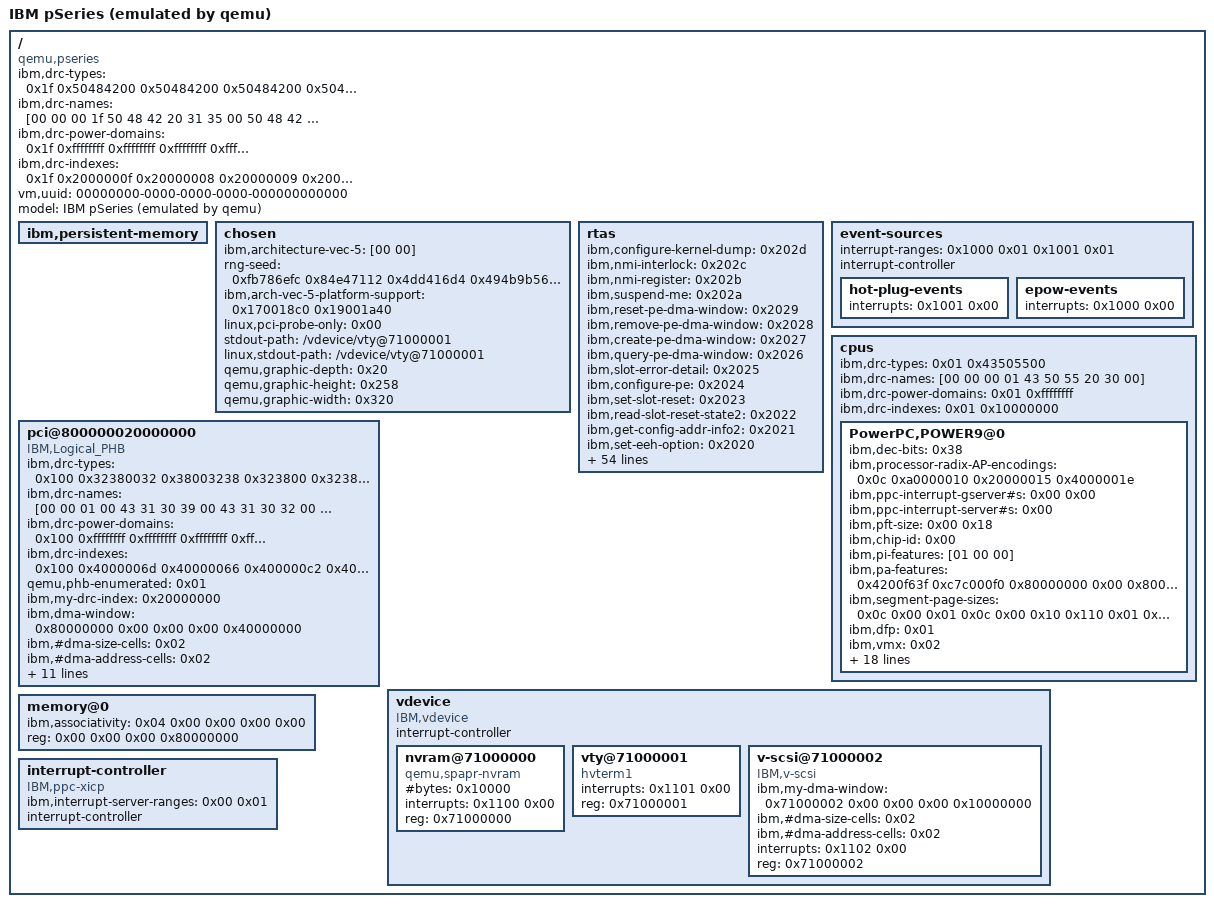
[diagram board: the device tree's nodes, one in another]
/dts-v1/;

/ {
	ibm,drc-types = <0x1f 0x50484200 0x50484200 0x50484200 0x50484200 0x50484200 0x50484200 0x50484200 0x50484200 0x50484200 0x50484200 0x50484200 0x50484200 0x50484200 0x50484200 0x50484200 0x50484200 0x50484200 0x50484200 0x50484200 0x50484200 0x50484200 0x50484200 0x50484200 0x50484200 0x50484200 0x50484200 0x50484200 0x50484200 0x50484200 0x50484200 0x50484200>;
	ibm,drc-names = [00 00 00 1f 50 48 42 20 31 35 00 50 48 42 20 38 00 50 48 42 20 39 00 50 48 42 20 31 36 00 50 48 42 20 31 37 00 50 48 42 20 31 38 00 50 48 42 20 31 39 00 50 48 42 20 32 36 00 50 48 42 20 32 30 00 50 48 42 20 32 37 00 50 48 42 20 32 31 00 50 48 42 20 32 38 00 50 48 42 20 32 39 00 50 48 42 20 32 32 00 50 48 42 20 33 30 00 50 48 42 20 32 33 00 50 48 42 20 32 34 00 50 48 42 20 32 35 00 50 48 42 20 30 00 50 48 42 20 31 00 50 48 42 20 32 00 50 48 42 20 31 30 00 50 48 42 20 33 00 50 48 42 20 31 31 00 50 48 42 20 34 00 50 48 42 20 31 32 00 50 48 42 20 35 00 50 48 42 20 31 33 00 50 48 42 20 36 00 50 48 42 20 31 34 00 50 48 42 20 37 00];
	ibm,drc-power-domains = <0x1f 0xffffffff 0xffffffff 0xffffffff 0xffffffff 0xffffffff 0xffffffff 0xffffffff 0xffffffff 0xffffffff 0xffffffff 0xffffffff 0xffffffff 0xffffffff 0xffffffff 0xffffffff 0xffffffff 0xffffffff 0xffffffff 0xffffffff 0xffffffff 0xffffffff 0xffffffff 0xffffffff 0xffffffff 0xffffffff 0xffffffff 0xffffffff 0xffffffff 0xffffffff 0xffffffff 0xffffffff>;
	ibm,drc-indexes = <0x1f 0x2000000f 0x20000008 0x20000009 0x20000010 0x20000011 0x20000012 0x20000013 0x2000001a 0x20000014 0x2000001b 0x20000015 0x2000001c 0x2000001d 0x20000016 0x2000001e 0x20000017 0x20000018 0x20000019 0x20000000 0x20000001 0x20000002 0x2000000a 0x20000003 0x2000000b 0x20000004 0x2000000c 0x20000005 0x2000000d 0x20000006 0x2000000e 0x20000007>;
	#size-cells = <0x02>;
	#address-cells = <0x02>;
	vm,uuid = "00000000-0000-0000-0000-000000000000";
	compatible = "qemu,pseries";
	model = "IBM pSeries (emulated by qemu)";
	device_type = "chrp";

	ibm,persistent-memory {
		device_type = "ibm,persistent-memory";
		#size-cells = <0x00>;
		#address-cells = <0x01>;
	};

	chosen {
		ibm,architecture-vec-5 = [00 00];
		rng-seed = <0xfb786efc 0x84e47112 0x4dd416d4 0x494b9b56 0x7fbd4a18 0x85047fd8 0xc287ff82 0xabd18130>;
		ibm,arch-vec-5-platform-support = <0x170018c0 0x19001a40>;
		linux,pci-probe-only = <0x00>;
		stdout-path = "/vdevice/vty@71000001";
		linux,stdout-path = "/vdevice/vty@71000001";
		qemu,graphic-depth = <0x20>;
		qemu,graphic-height = <0x258>;
		qemu,graphic-width = <0x320>;
	};

	rtas {
		ibm,configure-kernel-dump = <0x202d>;
		ibm,nmi-interlock = <0x202c>;
		ibm,nmi-register = <0x202b>;
		ibm,suspend-me = <0x202a>;
		ibm,reset-pe-dma-window = <0x2029>;
		ibm,remove-pe-dma-window = <0x2028>;
		ibm,create-pe-dma-window = <0x2027>;
		ibm,query-pe-dma-window = <0x2026>;
		ibm,slot-error-detail = <0x2025>;
		ibm,configure-pe = <0x2024>;
		ibm,set-slot-reset = <0x2023>;
		ibm,read-slot-reset-state2 = <0x2022>;
		ibm,get-config-addr-info2 = <0x2021>;
		ibm,set-eeh-option = <0x2020>;
		ibm,os-term = <0x201f>;
		ibm,configure-connector = <0x201e>;
		get-sensor-state = <0x201d>;
		get-power-level = <0x201c>;
		set-power-level = <0x201b>;
		set-indicator = <0x201a>;
		ibm,change-msi = <0x2019>;
		ibm,query-interrupt-source-number = <0x2018>;
		ibm,write-pci-config = <0x2017>;
		ibm,read-pci-config = <0x2016>;
		write-pci-config = <0x2015>;
		read-pci-config = <0x2014>;
		nvram-store = <0x2013>;
		nvram-fetch = <0x2012>;
		quiesce = <0x2011>;
		ibm,set-tce-bypass = <0x2010>;
		event-scan = <0x200f>;
		check-exception = <0x200e>;
		ibm,int-on = <0x200d>;
		ibm,int-off = <0x200c>;
		ibm,get-xive = <0x200b>;
		ibm,set-xive = <0x200a>;
		ibm,set-system-parameter = <0x2009>;
		ibm,get-system-parameter = <0x2008>;
		stop-self = <0x2007>;
		start-cpu = <0x2006>;
		query-cpu-stopped-state = <0x2005>;
		system-reboot = <0x2004>;
		power-off = <0x2003>;
		set-time-of-day = <0x2002>;
		get-time-of-day = <0x2001>;
		display-character = <0x2000>;
		ibm,configure-kernel-dump-sizes = <0x01 0x00 0x510 0x02 0x00 0x00>;
		ibm,configure-kernel-dump-version = <0x1000100>;
		ibm,lrdr-capacity = <0x00 0x80000000 0x00 0x10000000 0x01>;
		ibm,extended-os-term;
		ibm,change-msix-capable;
		rtas-event-scan-rate = <0x01>;
		rtas-error-log-max = <0x800>;
		rtas-size = <0x82c>;
		ibm,max-associativity-domains = <0x04 0x00 0x00 0x00 0x01>;
		ibm,associativity-reference-points = <0x04 0x04 0x02>;
		qemu,hypertas-functions = "hcall-memop1";
		ibm,hypertas-functions = "hcall-pft", "hcall-term", "hcall-dabr", "hcall-interrupt", "hcall-tce", "hcall-vio", "hcall-splpar", "hcall-join", "hcall-bulk", "hcall-set-mode", "hcall-sprg0", "hcall-copy", "hcall-debug", "hcall-vphn", "hcall-multi-tce", "hcall-hpt-resize", "hcall-watchdog";
	};

	event-sources {
		interrupt-ranges = <0x1000 0x01 0x1001 0x01>;
		#interrupt-cells = <0x02>;
		interrupt-controller;

		hot-plug-events {
			interrupts = <0x1001 0x00>;
		};

		epow-events {
			interrupts = <0x1000 0x00>;
		};
	};

	cpus {
		ibm,drc-types = <0x01 0x43505500>;
		ibm,drc-names = [00 00 00 01 43 50 55 20 30 00];
		ibm,drc-power-domains = <0x01 0xffffffff>;
		ibm,drc-indexes = <0x01 0x10000000>;
		#size-cells = <0x00>;
		#address-cells = <0x01>;

		PowerPC,POWER9@0 {
			ibm,dec-bits = <0x38>;
			ibm,processor-radix-AP-encodings = <0x0c 0xa0000010 0x20000015 0x4000001e>;
			ibm,ppc-interrupt-gserver#s = <0x00 0x00>;
			ibm,ppc-interrupt-server#s = <0x00>;
			ibm,pft-size = <0x00 0x18>;
			ibm,chip-id = <0x00>;
			ibm,pi-features = [01 00 00];
			ibm,pa-features = <0x4200f63f 0xc7c000f0 0x80000000 0x00 0x8000 0x80008000 0x8000 0x80008000 0x8000 0xc0000000 0x8000 0x80008000 0x80008000 0x80008000 0x80008000 0x80008000 0x80000000>;
			ibm,segment-page-sizes = <0x0c 0x00 0x01 0x0c 0x00 0x10 0x110 0x01 0x10 0x01>;
			ibm,dfp = <0x01>;
			ibm,vmx = <0x02>;
			ibm,processor-segment-sizes = <0x1c 0x28 0xffffffff 0xffffffff>;
			ibm,spurr = <0x01>;
			ibm,purr = <0x01>;
			64-bit;
			status = "okay";
			ibm,slb-size = <0x20>;
			slb-size = <0x20>;
			clock-frequency = <0x3b9aca00>;
			timebase-frequency = <0x1e848000>;
			i-cache-size = <0x8000>;
			d-cache-size = <0x8000>;
			i-cache-line-size = <0x80>;
			i-cache-block-size = <0x80>;
			d-cache-line-size = <0x80>;
			d-cache-block-size = <0x80>;
			cpu-version = <0x4e1202>;
			device_type = "cpu";
			reg = <0x00>;
			ibm,my-drc-index = <0x10000000>;
		};
	};

	pci@800000020000000 {
		ibm,drc-types = <0x100 0x32380032 0x38003238 0x323800 0x32380032 0x38003238 0x323800 0x32380032 0x38003238 0x323800 0x32380032 0x38003238 0x323800 0x32380032 0x38003238 0x323800 0x32380032 0x38003238 0x323800 0x32380032 0x38003238 0x323800 0x32380032 0x38003238 0x323800 0x32380032 0x38003238 0x323800 0x32380032 0x38003238 0x323800 0x32380032 0x38003238 0x323800 0x32380032 0x38003238 0x323800 0x32380032 0x38003238 0x323800 0x32380032 0x38003238 0x323800 0x32380032 0x38003238 0x323800 0x32380032 0x38003238 0x323800 0x32380032 0x38003238 0x323800 0x32380032 0x38003238 0x323800 0x32380032 0x38003238 0x323800 0x32380032 0x38003238 0x323800 0x32380032 0x38003238 0x323800 0x32380032 0x38003238 0x323800 0x32380032 0x38003238 0x323800 0x32380032 0x38003238 0x323800 0x32380032 0x38003238 0x323800 0x32380032 0x38003238 0x323800 0x32380032 0x38003238 0x323800 0x32380032 0x38003238 0x323800 0x32380032 0x38003238 0x323800 0x32380032 0x38003238 0x323800 0x32380032 0x38003238 0x323800 0x32380032 0x38003238 0x323800 0x32380032 0x38003238 0x323800 0x32380032 0x38003238 0x323800 0x32380032 0x38003238 0x323800 0x32380032 0x38003238 0x323800 0x32380032 0x38003238 0x323800 0x32380032 0x38003238 0x323800 0x32380032 0x38003238 0x323800 0x32380032 0x38003238 0x323800 0x32380032 0x38003238 0x323800 0x32380032 0x38003238 0x323800 0x32380032 0x38003238 0x323800 0x32380032 0x38003238 0x323800 0x32380032 0x38003238 0x323800 0x32380032 0x38003238 0x323800 0x32380032 0x38003238 0x323800 0x32380032 0x38003238 0x323800 0x32380032 0x38003238 0x323800 0x32380032 0x38003238 0x323800 0x32380032 0x38003238 0x323800 0x32380032 0x38003238 0x323800 0x32380032 0x38003238 0x323800 0x32380032 0x38003238 0x323800 0x32380032 0x38003238 0x323800 0x32380032 0x38003238 0x323800 0x32380032 0x38003238 0x323800 0x32380032 0x38003238 0x323800 0x32380032 0x38003238 0x323800 0x32380032 0x38003238 0x323800 0x32380032 0x38003238 0x323800 0x32380032 0x38003238 0x323800 0x32380032 0x38003238 0x323800 0x32380032 0x38003238 0x323800>;
		ibm,drc-names = [00 00 01 00 43 31 30 39 00 43 31 30 32 00 43 31 39 34 00 43 31 34 34 00 43 31 31 30 00 43 33 32 00 43 32 30 32 00 43 31 30 33 00 43 31 39 35 00 43 31 34 35 00 43 31 31 31 00 43 33 33 00 43 32 30 33 00 43 31 30 34 00 43 31 39 36 00 43 31 34 36 00 43 33 34 00 43 32 30 34 00 43 31 30 35 00 43 31 35 34 00 43 31 39 37 00 43 31 34 37 00 43 34 32 00 43 33 35 00 43 32 30 35 00 43 31 35 35 00 43 31 39 38 00 43 31 34 38 00 43 34 33 00 43 32 34 30 00 43 33 36 00 43 32 30 36 00 43 31 35 36 00 43 31 39 39 00 43 31 34 39 00 43 34 34 00 43 32 34 31 00 43 33 37 00 43 32 30 37 00 43 31 35 37 00 43 32 30 30 00 43 31 35 30 00 43 34 35 00 43 32 34 32 00 43 33 38 00 43 31 35 38 00 43 38 30 00 43 32 30 31 00 43 31 35 31 00 43 34 36 00 43 32 34 33 00 43 33 39 00 43 32 35 30 00 43 31 35 39 00 43 38 31 00 43 31 35 32 00 43 34 37 00 43 32 34 34 00 43 34 30 00 43 32 35 31 00 43 38 32 00 43 31 35 33 00 43 32 35 32 00 43 32 34 35 00 43 34 31 00 43 39 30 00 43 38 33 00 43 32 35 33 00 43 32 34 36 00 43 39 31 00 43 38 34 00 43 32 35 34 00 43 31 37 36 00 43 32 34 37 00 43 39 32 00 43 38 35 00 43 32 35 35 00 43 31 37 37 00 43 32 34 38 00 43 39 33 00 43 38 36 00 43 31 37 38 00 43 31 32 38 00 43 32 34 39 00 43 39 34 00 43 31 36 00 43 31 38 36 00 43 38 37 00 43 31 37 39 00 43 31 32 39 00 43 39 35 00 43 31 37 00 43 31 38 37 00 43 38 38 00 43 31 38 30 00 43 31 33 30 00 43 31 38 00 43 31 38 38 00 43 38 39 00 43 31 33 38 00 43 31 38 31 00 43 31 33 31 00 43 32 36 00 43 31 39 00 43 31 38 39 00 43 31 33 39 00 43 31 38 32 00 43 31 33 32 00 43 32 37 00 43 32 32 34 00 43 32 30 00 43 31 39 30 00 43 31 34 30 00 43 31 38 33 00 43 31 33 33 00 43 32 38 00 43 32 32 35 00 43 32 31 00 43 31 39 31 00 43 31 34 31 00 43 31 38 34 00 43 31 33 34 00 43 32 39 00 43 32 32 36 00 43 32 32 00 43 31 34 32 00 43 31 38 35 00 43 36 34 00 43 31 33 35 00 43 33 30 00 43 32 32 37 00 43 32 33 00 43 32 33 34 00 43 31 34 33 00 43 36 35 00 43 31 33 36 00 43 33 31 00 43 32 32 38 00 43 32 34 00 43 32 33 35 00 43 36 36 00 43 31 33 37 00 43 32 33 36 00 43 32 32 39 00 43 32 35 00 43 37 34 00 43 36 37 00 43 32 33 37 00 43 32 33 30 00 43 37 35 00 43 36 38 00 43 32 33 38 00 43 31 36 30 00 43 32 33 31 00 43 37 36 00 43 36 39 00 43 32 33 39 00 43 31 36 31 00 43 32 33 32 00 43 37 37 00 43 37 30 00 43 31 36 32 00 43 31 31 32 00 43 32 33 33 00 43 37 38 00 43 30 00 43 31 37 30 00 43 37 31 00 43 31 36 33 00 43 31 31 33 00 43 37 39 00 43 31 00 43 31 37 31 00 43 37 32 00 43 31 36 34 00 43 31 31 34 00 43 32 00 43 31 37 32 00 43 37 33 00 43 31 32 32 00 43 31 36 35 00 43 31 31 35 00 43 31 30 00 43 33 00 43 31 37 33 00 43 31 32 33 00 43 31 36 36 00 43 31 31 36 00 43 31 31 00 43 32 30 38 00 43 34 00 43 31 37 34 00 43 31 32 34 00 43 31 36 37 00 43 31 31 37 00 43 31 32 00 43 32 30 39 00 43 35 00 43 31 37 35 00 43 31 32 35 00 43 31 36 38 00 43 31 31 38 00 43 31 33 00 43 32 31 30 00 43 36 00 43 31 32 36 00 43 34 38 00 43 31 31 39 00 43 31 34 00 43 32 31 31 00 43 37 00 43 32 31 38 00 43 31 36 39 00 43 34 39 00 43 31 32 30 00 43 31 35 00 43 31 32 37 00 43 38 00 43 32 31 32 00 43 35 30 00 43 32 31 39 00 43 31 32 31 00 43 32 32 30 00 43 32 31 33 00 43 39 00 43 35 38 00 43 35 31 00 43 32 32 31 00 43 32 31 34 00 43 35 39 00 43 35 32 00 43 32 32 32 00 43 32 31 35 00 43 36 30 00 43 35 33 00 43 32 32 33 00 43 32 31 36 00 43 36 31 00 43 35 34 00 43 39 36 00 43 32 31 37 00 43 36 32 00 43 35 35 00 43 39 37 00 43 36 33 00 43 35 36 00 43 39 38 00 43 35 37 00 43 31 30 36 00 43 39 39 00 43 31 30 37 00 43 31 30 30 00 43 31 39 32 00 43 31 30 38 00 43 31 30 31 00 43 31 39 33 00];
		ibm,drc-power-domains = <0x100 0xffffffff 0xffffffff 0xffffffff 0xffffffff 0xffffffff 0xffffffff 0xffffffff 0xffffffff 0xffffffff 0xffffffff 0xffffffff 0xffffffff 0xffffffff 0xffffffff 0xffffffff 0xffffffff 0xffffffff 0xffffffff 0xffffffff 0xffffffff 0xffffffff 0xffffffff 0xffffffff 0xffffffff 0xffffffff 0xffffffff 0xffffffff 0xffffffff 0xffffffff 0xffffffff 0xffffffff 0xffffffff 0xffffffff 0xffffffff 0xffffffff 0xffffffff 0xffffffff 0xffffffff 0xffffffff 0xffffffff 0xffffffff 0xffffffff 0xffffffff 0xffffffff 0xffffffff 0xffffffff 0xffffffff 0xffffffff 0xffffffff 0xffffffff 0xffffffff 0xffffffff 0xffffffff 0xffffffff 0xffffffff 0xffffffff 0xffffffff 0xffffffff 0xffffffff 0xffffffff 0xffffffff 0xffffffff 0xffffffff 0xffffffff 0xffffffff 0xffffffff 0xffffffff 0xffffffff 0xffffffff 0xffffffff 0xffffffff 0xffffffff 0xffffffff 0xffffffff 0xffffffff 0xffffffff 0xffffffff 0xffffffff 0xffffffff 0xffffffff 0xffffffff 0xffffffff 0xffffffff 0xffffffff 0xffffffff 0xffffffff 0xffffffff 0xffffffff 0xffffffff 0xffffffff 0xffffffff 0xffffffff 0xffffffff 0xffffffff 0xffffffff 0xffffffff 0xffffffff 0xffffffff 0xffffffff 0xffffffff 0xffffffff 0xffffffff 0xffffffff 0xffffffff 0xffffffff 0xffffffff 0xffffffff 0xffffffff 0xffffffff 0xffffffff 0xffffffff 0xffffffff 0xffffffff 0xffffffff 0xffffffff 0xffffffff 0xffffffff 0xffffffff 0xffffffff 0xffffffff 0xffffffff 0xffffffff 0xffffffff 0xffffffff 0xffffffff 0xffffffff 0xffffffff 0xffffffff 0xffffffff 0xffffffff 0xffffffff 0xffffffff 0xffffffff 0xffffffff 0xffffffff 0xffffffff 0xffffffff 0xffffffff 0xffffffff 0xffffffff 0xffffffff 0xffffffff 0xffffffff 0xffffffff 0xffffffff 0xffffffff 0xffffffff 0xffffffff 0xffffffff 0xffffffff 0xffffffff 0xffffffff 0xffffffff 0xffffffff 0xffffffff 0xffffffff 0xffffffff 0xffffffff 0xffffffff 0xffffffff 0xffffffff 0xffffffff 0xffffffff 0xffffffff 0xffffffff 0xffffffff 0xffffffff 0xffffffff 0xffffffff 0xffffffff 0xffffffff 0xffffffff 0xffffffff 0xffffffff 0xffffffff 0xffffffff 0xffffffff 0xffffffff 0xffffffff 0xffffffff 0xffffffff 0xffffffff 0xffffffff 0xffffffff 0xffffffff 0xffffffff 0xffffffff 0xffffffff 0xffffffff 0xffffffff 0xffffffff 0xffffffff 0xffffffff 0xffffffff 0xffffffff 0xffffffff 0xffffffff 0xffffffff 0xffffffff 0xffffffff 0xffffffff 0xffffffff 0xffffffff 0xffffffff 0xffffffff 0xffffffff 0xffffffff 0xffffffff 0xffffffff 0xffffffff 0xffffffff 0xffffffff 0xffffffff 0xffffffff 0xffffffff 0xffffffff 0xffffffff 0xffffffff 0xffffffff 0xffffffff 0xffffffff 0xffffffff 0xffffffff 0xffffffff 0xffffffff 0xffffffff 0xffffffff 0xffffffff 0xffffffff 0xffffffff 0xffffffff 0xffffffff 0xffffffff 0xffffffff 0xffffffff 0xffffffff 0xffffffff 0xffffffff 0xffffffff 0xffffffff 0xffffffff 0xffffffff 0xffffffff 0xffffffff 0xffffffff 0xffffffff 0xffffffff 0xffffffff 0xffffffff 0xffffffff 0xffffffff 0xffffffff 0xffffffff 0xffffffff 0xffffffff 0xffffffff>;
		ibm,drc-indexes = <0x100 0x4000006d 0x40000066 0x400000c2 0x40000090 0x4000006e 0x40000020 0x400000ca 0x40000067 0x400000c3 0x40000091 0x4000006f 0x40000021 0x400000cb 0x40000068 0x400000c4 0x40000092 0x40000022 0x400000cc 0x40000069 0x4000009a 0x400000c5 0x40000093 0x4000002a 0x40000023 0x400000cd 0x4000009b 0x400000c6 0x40000094 0x4000002b 0x400000f0 0x40000024 0x400000ce 0x4000009c 0x400000c7 0x40000095 0x4000002c 0x400000f1 0x40000025 0x400000cf 0x4000009d 0x400000c8 0x40000096 0x4000002d 0x400000f2 0x40000026 0x4000009e 0x40000050 0x400000c9 0x40000097 0x4000002e 0x400000f3 0x40000027 0x400000fa 0x4000009f 0x40000051 0x40000098 0x4000002f 0x400000f4 0x40000028 0x400000fb 0x40000052 0x40000099 0x400000fc 0x400000f5 0x40000029 0x4000005a 0x40000053 0x400000fd 0x400000f6 0x4000005b 0x40000054 0x400000fe 0x400000b0 0x400000f7 0x4000005c 0x40000055 0x400000ff 0x400000b1 0x400000f8 0x4000005d 0x40000056 0x400000b2 0x40000080 0x400000f9 0x4000005e 0x40000010 0x400000ba 0x40000057 0x400000b3 0x40000081 0x4000005f 0x40000011 0x400000bb 0x40000058 0x400000b4 0x40000082 0x40000012 0x400000bc 0x40000059 0x4000008a 0x400000b5 0x40000083 0x4000001a 0x40000013 0x400000bd 0x4000008b 0x400000b6 0x40000084 0x4000001b 0x400000e0 0x40000014 0x400000be 0x4000008c 0x400000b7 0x40000085 0x4000001c 0x400000e1 0x40000015 0x400000bf 0x4000008d 0x400000b8 0x40000086 0x4000001d 0x400000e2 0x40000016 0x4000008e 0x400000b9 0x40000040 0x40000087 0x4000001e 0x400000e3 0x40000017 0x400000ea 0x4000008f 0x40000041 0x40000088 0x4000001f 0x400000e4 0x40000018 0x400000eb 0x40000042 0x40000089 0x400000ec 0x400000e5 0x40000019 0x4000004a 0x40000043 0x400000ed 0x400000e6 0x4000004b 0x40000044 0x400000ee 0x400000a0 0x400000e7 0x4000004c 0x40000045 0x400000ef 0x400000a1 0x400000e8 0x4000004d 0x40000046 0x400000a2 0x40000070 0x400000e9 0x4000004e 0x40000000 0x400000aa 0x40000047 0x400000a3 0x40000071 0x4000004f 0x40000001 0x400000ab 0x40000048 0x400000a4 0x40000072 0x40000002 0x400000ac 0x40000049 0x4000007a 0x400000a5 0x40000073 0x4000000a 0x40000003 0x400000ad 0x4000007b 0x400000a6 0x40000074 0x4000000b 0x400000d0 0x40000004 0x400000ae 0x4000007c 0x400000a7 0x40000075 0x4000000c 0x400000d1 0x40000005 0x400000af 0x4000007d 0x400000a8 0x40000076 0x4000000d 0x400000d2 0x40000006 0x4000007e 0x40000030 0x40000077 0x4000000e 0x400000d3 0x40000007 0x400000da 0x400000a9 0x40000031 0x40000078 0x4000000f 0x4000007f 0x40000008 0x400000d4 0x40000032 0x400000db 0x40000079 0x400000dc 0x400000d5 0x40000009 0x4000003a 0x40000033 0x400000dd 0x400000d6 0x4000003b 0x40000034 0x400000de 0x400000d7 0x4000003c 0x40000035 0x400000df 0x400000d8 0x4000003d 0x40000036 0x40000060 0x400000d9 0x4000003e 0x40000037 0x40000061 0x4000003f 0x40000038 0x40000062 0x40000039 0x4000006a 0x40000063 0x4000006b 0x40000064 0x400000c0 0x4000006c 0x40000065 0x400000c1>;
		#size-cells = <0x02>;
		#address-cells = <0x03>;
		qemu,phb-enumerated = <0x01>;
		ibm,my-drc-index = <0x20000000>;
		ibm,dma-window = <0x80000000 0x00 0x00 0x00 0x40000000>;
		ibm,#dma-size-cells = <0x02>;
		ibm,#dma-address-cells = <0x02>;
		interrupt-map = <0x00 0x00 0x00 0x01 0x1111 0x1200 0x01 0x00 0x00 0x00 0x02 0x1111 0x1201 0x01 0x00 0x00 0x00 0x03 0x1111 0x1202 0x01 0x00 0x00 0x00 0x04 0x1111 0x1203 0x01 0x800 0x00 0x00 0x01 0x1111 0x1201 0x01 0x800 0x00 0x00 0x02 0x1111 0x1202 0x01 0x800 0x00 0x00 0x03 0x1111 0x1203 0x01 0x800 0x00 0x00 0x04 0x1111 0x1200 0x01 0x1000 0x00 0x00 0x01 0x1111 0x1202 0x01 0x1000 0x00 0x00 0x02 0x1111 0x1203 0x01 0x1000 0x00 0x00 0x03 0x1111 0x1200 0x01 0x1000 0x00 0x00 0x04 0x1111 0x1201 0x01 0x1800 0x00 0x00 0x01 0x1111 0x1203 0x01 0x1800 0x00 0x00 0x02 0x1111 0x1200 0x01 0x1800 0x00 0x00 0x03 0x1111 0x1201 0x01 0x1800 0x00 0x00 0x04 0x1111 0x1202 0x01 0x2000 0x00 0x00 0x01 0x1111 0x1200 0x01 0x2000 0x00 0x00 0x02 0x1111 0x1201 0x01 0x2000 0x00 0x00 0x03 0x1111 0x1202 0x01 0x2000 0x00 0x00 0x04 0x1111 0x1203 0x01 0x2800 0x00 0x00 0x01 0x1111 0x1201 0x01 0x2800 0x00 0x00 0x02 0x1111 0x1202 0x01 0x2800 0x00 0x00 0x03 0x1111 0x1203 0x01 0x2800 0x00 0x00 0x04 0x1111 0x1200 0x01 0x3000 0x00 0x00 0x01 0x1111 0x1202 0x01 0x3000 0x00 0x00 0x02 0x1111 0x1203 0x01 0x3000 0x00 0x00 0x03 0x1111 0x1200 0x01 0x3000 0x00 0x00 0x04 0x1111 0x1201 0x01 0x3800 0x00 0x00 0x01 0x1111 0x1203 0x01 0x3800 0x00 0x00 0x02 0x1111 0x1200 0x01 0x3800 0x00 0x00 0x03 0x1111 0x1201 0x01 0x3800 0x00 0x00 0x04 0x1111 0x1202 0x01 0x4000 0x00 0x00 0x01 0x1111 0x1200 0x01 0x4000 0x00 0x00 0x02 0x1111 0x1201 0x01 0x4000 0x00 0x00 0x03 0x1111 0x1202 0x01 0x4000 0x00 0x00 0x04 0x1111 0x1203 0x01 0x4800 0x00 0x00 0x01 0x1111 0x1201 0x01 0x4800 0x00 0x00 0x02 0x1111 0x1202 0x01 0x4800 0x00 0x00 0x03 0x1111 0x1203 0x01 0x4800 0x00 0x00 0x04 0x1111 0x1200 0x01 0x5000 0x00 0x00 0x01 0x1111 0x1202 0x01 0x5000 0x00 0x00 0x02 0x1111 0x1203 0x01 0x5000 0x00 0x00 0x03 0x1111 0x1200 0x01 0x5000 0x00 0x00 0x04 0x1111 0x1201 0x01 0x5800 0x00 0x00 0x01 0x1111 0x1203 0x01 0x5800 0x00 0x00 0x02 0x1111 0x1200 0x01 0x5800 0x00 0x00 0x03 0x1111 0x1201 0x01 0x5800 0x00 0x00 0x04 0x1111 0x1202 0x01 0x6000 0x00 0x00 0x01 0x1111 0x1200 0x01 0x6000 0x00 0x00 0x02 0x1111 0x1201 0x01 0x6000 0x00 0x00 0x03 0x1111 0x1202 0x01 0x6000 0x00 0x00 0x04 0x1111 0x1203 0x01 0x6800 0x00 0x00 0x01 0x1111 0x1201 0x01 0x6800 0x00 0x00 0x02 0x1111 0x1202 0x01 0x6800 0x00 0x00 0x03 0x1111 0x1203 0x01 0x6800 0x00 0x00 0x04 0x1111 0x1200 0x01 0x7000 0x00 0x00 0x01 0x1111 0x1202 0x01 0x7000 0x00 0x00 0x02 0x1111 0x1203 0x01 0x7000 0x00 0x00 0x03 0x1111 0x1200 0x01 0x7000 0x00 0x00 0x04 0x1111 0x1201 0x01 0x7800 0x00 0x00 0x01 0x1111 0x1203 0x01 0x7800 0x00 0x00 0x02 0x1111 0x1200 0x01 0x7800 0x00 0x00 0x03 0x1111 0x1201 0x01 0x7800 0x00 0x00 0x04 0x1111 0x1202 0x01 0x8000 0x00 0x00 0x01 0x1111 0x1200 0x01 0x8000 0x00 0x00 0x02 0x1111 0x1201 0x01 0x8000 0x00 0x00 0x03 0x1111 0x1202 0x01 0x8000 0x00 0x00 0x04 0x1111 0x1203 0x01 0x8800 0x00 0x00 0x01 0x1111 0x1201 0x01 0x8800 0x00 0x00 0x02 0x1111 0x1202 0x01 0x8800 0x00 0x00 0x03 0x1111 0x1203 0x01 0x8800 0x00 0x00 0x04 0x1111 0x1200 0x01 0x9000 0x00 0x00 0x01 0x1111 0x1202 0x01 0x9000 0x00 0x00 0x02 0x1111 0x1203 0x01 0x9000 0x00 0x00 0x03 0x1111 0x1200 0x01 0x9000 0x00 0x00 0x04 0x1111 0x1201 0x01 0x9800 0x00 0x00 0x01 0x1111 0x1203 0x01 0x9800 0x00 0x00 0x02 0x1111 0x1200 0x01 0x9800 0x00 0x00 0x03 0x1111 0x1201 0x01 0x9800 0x00 0x00 0x04 0x1111 0x1202 0x01 0xa000 0x00 0x00 0x01 0x1111 0x1200 0x01 0xa000 0x00 0x00 0x02 0x1111 0x1201 0x01 0xa000 0x00 0x00 0x03 0x1111 0x1202 0x01 0xa000 0x00 0x00 0x04 0x1111 0x1203 0x01 0xa800 0x00 0x00 0x01 0x1111 0x1201 0x01 0xa800 0x00 0x00 0x02 0x1111 0x1202 0x01 0xa800 0x00 0x00 0x03 0x1111 0x1203 0x01 0xa800 0x00 0x00 0x04 0x1111 0x1200 0x01 0xb000 0x00 0x00 0x01 0x1111 0x1202 0x01 0xb000 0x00 0x00 0x02 0x1111 0x1203 0x01 0xb000 0x00 0x00 0x03 0x1111 0x1200 0x01 0xb000 0x00 0x00 0x04 0x1111 0x1201 0x01 0xb800 0x00 0x00 0x01 0x1111 0x1203 0x01 0xb800 0x00 0x00 0x02 0x1111 0x1200 0x01 0xb800 0x00 0x00 0x03 0x1111 0x1201 0x01 0xb800 0x00 0x00 0x04 0x1111 0x1202 0x01 0xc000 0x00 0x00 0x01 0x1111 0x1200 0x01 0xc000 0x00 0x00 0x02 0x1111 0x1201 0x01 0xc000 0x00 0x00 0x03 0x1111 0x1202 0x01 0xc000 0x00 0x00 0x04 0x1111 0x1203 0x01 0xc800 0x00 0x00 0x01 0x1111 0x1201 0x01 0xc800 0x00 0x00 0x02 0x1111 0x1202 0x01 0xc800 0x00 0x00 0x03 0x1111 0x1203 0x01 0xc800 0x00 0x00 0x04 0x1111 0x1200 0x01 0xd000 0x00 0x00 0x01 0x1111 0x1202 0x01 0xd000 0x00 0x00 0x02 0x1111 0x1203 0x01 0xd000 0x00 0x00 0x03 0x1111 0x1200 0x01 0xd000 0x00 0x00 0x04 0x1111 0x1201 0x01 0xd800 0x00 0x00 0x01 0x1111 0x1203 0x01 0xd800 0x00 0x00 0x02 0x1111 0x1200 0x01 0xd800 0x00 0x00 0x03 0x1111 0x1201 0x01 0xd800 0x00 0x00 0x04 0x1111 0x1202 0x01 0xe000 0x00 0x00 0x01 0x1111 0x1200 0x01 0xe000 0x00 0x00 0x02 0x1111 0x1201 0x01 0xe000 0x00 0x00 0x03 0x1111 0x1202 0x01 0xe000 0x00 0x00 0x04 0x1111 0x1203 0x01 0xe800 0x00 0x00 0x01 0x1111 0x1201 0x01 0xe800 0x00 0x00 0x02 0x1111 0x1202 0x01 0xe800 0x00 0x00 0x03 0x1111 0x1203 0x01 0xe800 0x00 0x00 0x04 0x1111 0x1200 0x01 0xf000 0x00 0x00 0x01 0x1111 0x1202 0x01 0xf000 0x00 0x00 0x02 0x1111 0x1203 0x01 0xf000 0x00 0x00 0x03 0x1111 0x1200 0x01 0xf000 0x00 0x00 0x04 0x1111 0x1201 0x01 0xf800 0x00 0x00 0x01 0x1111 0x1203 0x01 0xf800 0x00 0x00 0x02 0x1111 0x1200 0x01 0xf800 0x00 0x00 0x03 0x1111 0x1201 0x01 0xf800 0x00 0x00 0x04 0x1111 0x1202 0x01>;
		interrupt-map-mask = <0xf800 0x00 0x00 0xffffffff>;
		ibm,ddw-extensions = <0x02 0x2029 0x01>;
		ibm,ddw-applicable = <0x2026 0x2027 0x2028>;
		ibm,pe-total-#msi = <0xd00>;
		ibm,pci-config-space-type = <0x01>;
		reg = <0x8000000 0x20000000 0x00 0x00>;
		ranges = <0x1000000 0x00 0x00 0x2000 0x00 0x00 0x10000 0x2000000 0x00 0x80000000 0x2000 0x80000000 0x00 0x80000000 0x3000000 0x2100 0x00 0x2100 0x00 0x100 0x00>;
		bus-range = <0x00 0xff>;
		used-by-rtas;
		#interrupt-cells = <0x01>;
		compatible = "IBM,Logical_PHB";
		device_type = "pci";
	};

	vdevice {
		interrupt-controller;
		#interrupt-cells = <0x02>;
		#size-cells = <0x00>;
		#address-cells = <0x01>;
		compatible = "IBM,vdevice";
		device_type = "vdevice";

		nvram@71000000 {
			#bytes = <0x10000>;
			interrupts = <0x1100 0x00>;
			compatible = "qemu,spapr-nvram";
			device_type = "nvram";
			reg = <0x71000000>;
		};

		vty@71000001 {
			interrupts = <0x1101 0x00>;
			compatible = "hvterm1";
			device_type = "serial";
			reg = <0x71000001>;
		};

		v-scsi@71000002 {
			#size-cells = <0x00>;
			#address-cells = <0x02>;
			ibm,my-dma-window = <0x71000002 0x00 0x00 0x00 0x10000000>;
			ibm,#dma-size-cells = <0x02>;
			ibm,#dma-address-cells = <0x02>;
			interrupts = <0x1102 0x00>;
			compatible = "IBM,v-scsi";
			device_type = "vscsi";
			reg = <0x71000002>;
		};
	};

	memory@0 {
		ibm,associativity = <0x04 0x00 0x00 0x00 0x00>;
		reg = <0x00 0x00 0x00 0x80000000>;
		device_type = "memory";
	};

	interrupt-controller {
		phandle = <0x1111>;
		linux,phandle = <0x1111>;
		#interrupt-cells = <0x02>;
		ibm,interrupt-server-ranges = <0x00 0x01>;
		interrupt-controller;
		compatible = "IBM,ppc-xicp";
		device_type = "PowerPC-External-Interrupt-Presentation";
	};
};
